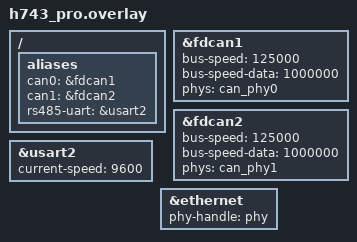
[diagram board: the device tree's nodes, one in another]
/**
 * 野火 STM32H743 Pro 设备树 overlay
 * FDCAN + UART/RS-485 + ETH + SRAM
 */

/* FDCAN1 */
&fdcan1 {
	status = "okay";
	bus-speed = <125000>;
	bus-speed-data = <1000000>;
	phys = <&can_phy0>;
};

/* FDCAN2 */
&fdcan2 {
	status = "okay";
	bus-speed = <125000>;
	bus-speed-data = <1000000>;
	phys = <&can_phy1>;
};

/* 串口用于 RS-485 */
&usart2 {
	status = "okay";
	current-speed = <9600>;
};

/* ETH 以太网 */
&ethernet {
	status = "okay";
	phy-handle = <&phy>;
};

/* aliases */
/ {
	aliases {
		can0 = &fdcan1;
		can1 = &fdcan2;
		rs485-uart = &usart2;
	};
};
